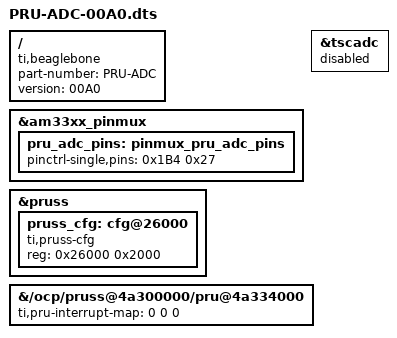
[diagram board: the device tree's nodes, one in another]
/*
 * Device Tree Overlay for PRU ADC Sampling
 * Enables PRU with OCP master access and configures AIN1 (P9_40) for analog input
 */

/dts-v1/;
/plugin/;

/ {
    compatible = "ti,beaglebone", "ti,beaglebone-black", "ti,am33xx";

    /* Identification */
    part-number = "PRU-ADC";
    version = "00A0";

    /* Pin configuration */
    fragment@0 {
        target = <&am33xx_pinmux>;
        __overlay__ {
            pru_adc_pins: pinmux_pru_adc_pins {
                pinctrl-single,pins = <
                    /* P9_40: AIN1 - Analog Input */
                    0x1B4 0x27  /* gpio0[20], MODE7 | INPUT | PULLDOWN */
                >;
            };
        };
    };

    /* Disable Linux IIO ADC driver to free ADC for PRU access */
    fragment@1 {
        target = <&tscadc>;
        __overlay__ {
            status = "disabled";
        };
    };

    /* Enable and configure PRU with OCP master access */
    fragment@2 {
        target = <&pruss>;
        __overlay__ {
            status = "okay";

            /* Enable OCP master port for peripheral access */
            pruss_cfg: cfg@26000 {
                compatible = "ti,pruss-cfg", "syscon";
                reg = <0x26000 0x2000>;
                #address-cells = <1>;
                #size-cells = <1>;
                ranges = <0x0 0x26000 0x2000>;
            };
        };
    };

    /* Configure PRU0 for ADC access */
    fragment@3 {
        target-path = "/ocp/pruss@4a300000/pru@4a334000";
        __overlay__ {
            /* Grant PRU0 access to ADC memory region */
            ti,pru-interrupt-map = <0 0 0>;
        };
    };
};
